# CC27x0 register map
File version: 1.0
CPU: CM4 r0p4, little endian, no MPU, no FPU, VTOR, 3 interrupt priority bits
Registers are 32-bit, read-write, reset 0x0 unless marked. A register's access mark holds for its fields unless they carry their own. Offsets are from the block's base; [hi:lo] are bit positions; {n}, {i} and the like mark numbered series.

## SYS0 — This is top module of SYS0
Base 0x40004000
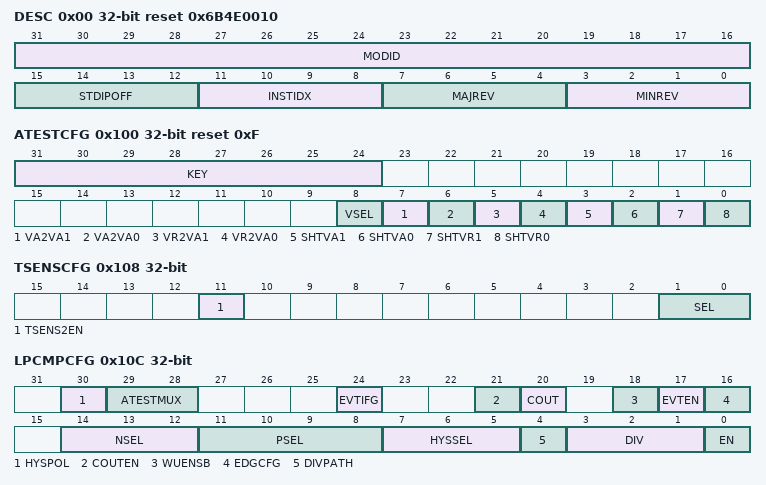
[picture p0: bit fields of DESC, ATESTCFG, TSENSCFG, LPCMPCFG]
0x00 DESC ro reset 0x6B4E0010 — Description Register This register provides IP module ID, revision information, instance index and standard MMR registers offset.
  [31:16] MODID — Module Identifier is used to uniquely identify this IP
  [15:12] STDIPOFF — Standard IP MMR block offset. Standard IP MMRs are the set from aggregated IRQ registers till DTB. 0: Standard IP MMRs do not exist 0x1-0xF: Standard IP MMRs begin at offset of (64*STDIPOFF from the base IP address)
  [11:8] INSTIDX — IP Instance ID number. If multiple instances of IP exist in the device, this field can identify the instance number (0-15).
  [7:4] MAJREV — Major revision of IP (0-15).
  [3:0] MINREV — Minor revision of IP (0-15).
0x0C MUNLOCK wo — Mutable section Unlock This register unlocks registers in mutable section
  [31:0] KEY — Write the unlock key 0xC5AF6927 to temporarily unlock registers in mutable section. The lock is set automatically if no write accesses, to the mutable section, are detected for consecutive 32 CLKULL (24MHz) clock cycles. Writing any value other than that, the unlock key will immediately lock the mutable register space for write access.
    0xC5AF6927=UNLOCK (Unlock registers in the mutable section); 0=LOCK (Lock registers in the mutable section)
0x100 ATESTCFG reset 0xF — ATEST Configuration This register is used to configure analog switches in ATEST module.
  [31:24] KEY wo — Key must be written with value 0x5A for successful write to ATESTCFG and to unlock register state. Write with any value other than 0x5A to KEY will be ignored and register content is not updated. It is recommended to write this register with incorrect KEY to lock back register state after necessary ATESTCFG updates are done. Read value of KEY is 0x0.
  [8] VSEL — Selects supply for ATEST switches.
    1=VDDS (Selects VDDS); 0=VDDBST (Selects VDDBOOST)
  [7] VA2VA1 — Enables isolation switch between VA_ATEST_A1 and VA_PAD_A1.
    1=CLOSE (Switch is closed); 0=OPEN (Switch is open)
  [6] VA2VA0 — Enables isolation switch between VA_ATEST_A0 and VA_PAD_A0.
    1=CLOSE (Switch is closed); 0=OPEN (Switch is open)
  [5] VR2VA1 — Enables isolation switch between VR_ATEST_A1 and VA_ATEST_A1.
    1=CLOSE (Switch is closed); 0=OPEN (Switch is open)
  [4] VR2VA0 — Enables isolation switch between VR_ATEST_A0 and VA_ATEST_A0.
    1=CLOSE (Switch is closed); 0=OPEN (Switch is open)
  [3] SHTVA1 — Shorts VA_ATEST_A1 to ground.
    1=CLOSE (Switch is closed); 0=OPEN (Switch is open)
  [2] SHTVA0 — Shorts VA_ATEST_A0 to ground.
    1=CLOSE (Switch is closed); 0=OPEN (Switch is open)
  [1] SHTVR1 — Shorts VR_ATEST_A1 to ground.
    1=CLOSE (Switch is closed); 0=OPEN (Switch is open)
  [0] SHTVR0 — Shorts VR_ATEST_A0 to ground.
    1=CLOSE (Switch is closed); 0=OPEN (Switch is open)
0x108 TSENSCFG — TSENSE Configuration This register is used to configure temperature sensor module.
  [11] TSENS2EN — This is the enable bit for the second temperature sensor in AUX.
    1=EN (Second temperature sensor is enabled.); 0=DIS (Second temperature sensor is disabled.)
  [1:0] SEL — Used to enable and configure temperature sensor module. Setting the value to 0x3 will disable the temperature sensor.
    2=GND (20uA current is injected on VR_ATEST_A0 and ground measured on VR_ATEST_A1); 1=VALUE (20uA current is injected on VR_ATEST_A0 and voltage measured on VR_ATEST_A1); 0=DISABLE (Temperature sensor is disabled)
0x10C LPCMPCFG — LPCMP configuration This register is used to configure and check the status of low-power comparator (LPCOMP) module.
  [30] HYSPOL — Hysteresis polarity
    1=INV (Inverted); 0=NOINV (Not inverted)
  [29:28] ATESTMUX — Used to configure ATEST mux in comparator module and provides chosen output on VA_ATEST_A0. Note: This bit field is write-protected using global lock indicator on production device.
    3=IBIASOUT (Selects bias current output); 2=COMP_VIN_NEG (Selects voltage divider output); 1=COMPOUT (Selects comparator output); 0=OFF (ATEST mux is off)
  [24] EVTIFG — Event flag The event flag is set when the comparator output transition is qualified based on the edge polarity configuration in EDGCFG.
    1=SET; 0=CLR (Clear)
  [21] COUTEN — Enables LPCOMP output on device pin.
    1=EN (Enabled); 0=DIS (Disabled)
  [20] COUT ro — LPCOMP output status. This bit captures the value LPCOMP raw output.
    1=HIGH (Output is high); 0=LOW (Output is low)
  [18] WUENSB — Enables lpcmpcfg output to wake device from standby.
    1=EN (Enable); 0=DIS (Disable)
  [17] EVTEN — Enables event generation. Comparator module will produce event on ULL event fabric when EVTIFG is set.
    1=EN (Enable); 0=DIS (Disable)
  [16] EDGCFG — Selects positive edge or negative edge detection on comparator output to set the event flag
    1=FALL (Fall edge detection); 0=RISE (Rise edge detection)
  [14:12] NSEL — Negative input selection. Setting values 0x5-0x7 will open all the switches.
    4=VDDD (Selects VDDD); 3=VDDS (Selects VDDS); 2=VA_PAD_A3 (Selects VA_PAD_A3); 1=VA_PAD_A2 (Selects VA_PAD_A2); 0=OPEN (All switches are open)
  [11:8] PSEL — Positive input selection. Setting values 0x9-0xF will open all the switches.
    8=VDDS (Selects VDDS); 7=VA_ATEST_A1 (Selects VA_ATEST_A1); 6=VA_ATEST_A0 (Selects VA_ATEST_A0); 5=VR_ATEST_A1 (Selects VR_ATEST_A1); 4=VR_ATEST_A0 (Selects VR_ATEST_A0); 3=VA_PAD_A3 (Selects VA_PAD_A3); 2=VA_PAD_A2 (Selects VA_PAD_A2); 1=VA_PAD_A1 (Selects VA_PAD_A1); 0=OPEN (All switches are open)
  [7:5] HYSSEL — Used to enable and select hysteresis level Hysteresis is disabled when HYSSEL = 0 and enabled for other values of HYSSEL from 1 to 7. Refer to device specific datasheet for individual hysteresis values.
    {v}=Hysteresis value {v} (v=1..7); 0=Hysteresis is disabled
  [4] DIVPATH — Used to select the path on which voltage divider is applied
    1=PSIDE (Divider is applied on P-side); 0=NSIDE (Divider is applied on N-side)
  [3:1] DIV — Used to configure reference divider. Setting values 0x5-0x7 will set the divide value to 1.
    4=Divide value is 1/4; 3=Divide value is 1/3; 2=Divide value is 1/2; 1=Divide value is 3/4; 0=Divide value is 1
  [0] EN — Used to enable comparator module.
    1=EN (Enable); 0=DIS (Disable)
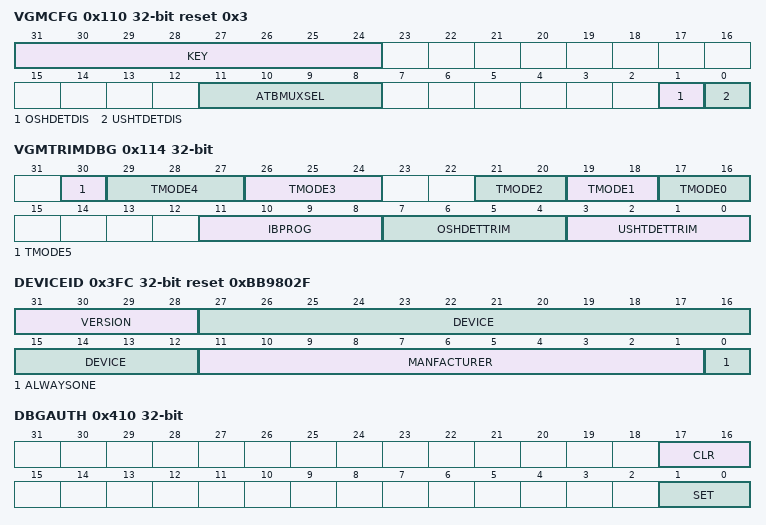
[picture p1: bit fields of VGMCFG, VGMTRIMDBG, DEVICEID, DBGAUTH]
0x110 VGMCFG reset 0x3 — This register is used to configure the VGM module.
  [31:24] KEY wo — Key must be written with value 0x5A for successful write to VGMCFG and to unlock register state. Write with any value other than 0x5A to KEY will be ignored and the register content is not updated. Read value of KEY is 0x0.
  [11:8] ATBMUXSEL — These bits are used to generate VGM ATB mux selection control.
  [1] OSHDETDIS — Disables overshoot detector in VGM.
    1=DIS (Disable); 0=EN (Enable)
  [0] USHTDETDIS — Disables undershoot detector in VGM.
    1=DIS (Disable); 0=EN (Enable)
0x114 VGMTRIMDBG — This register is used to trim and debug VGM module.
  [30] TMODE5 — Test mode bit for glitchy supply mux selection.
  [29:27] TMODE4 — Test mode bits for VREF mux selection for overshoot detector.
  [26:24] TMODE3 — Test mode bits for VREF mux selection for undershoot detector.
  [21:20] TMODE2 — Test mode for level shifter isolation.
  [19:18] TMODE1 — Test mode bits for low voltage SR latch reset.
  [17:16] TMODE0 — Test mode bits for 3V SR latch reset.
  [11:8] IBPROG — These bits are used to program VGM bias current generator.
  [7:4] OSHDETTRIM — These bits are used to trim VGM overshoot detector.
  [3:0] USHTDETTRIM — These bits are used to trim VGM undershoot detector.
0x3FC DEVICEID ro reset 0xBB9802F — Device ID This register provides Device ID information. Note: This 32-bit register value is provided as output to DEBUGSS.
  [31:28] VERSION — Monotonic increasing value indicating new hardware revision. A newer hardware revision shall never have a lower version than an older revision of hardware.
  [27:12] DEVICE — Value generated by RAMP for the SOC. This value uniquely identifies the die from any other TI device.
  [11:1] MANFACTURER — JEP 106 assigned manufacturer ID. This field identifies the device as a Texas Instruments device.
  [0] ALWAYSONE — Value 1 in this bit field means that a 32-bit scan register exists.
0x410 DBGAUTH wo — Debug Authentication. This register is used by ROM to store Debug Authnetication Status
  [17:16] CLR — Clears Authentication Status
  [1:0] SET — Sets Authentication Status
    3=SEC (Secure Debug Authorized); 2=NONSEC (Non-Secure Debug Authorized); 1=NONINV (Only Non-Invasive Debug Authorized); 0=UNAUTH (Debug Unauthorized)
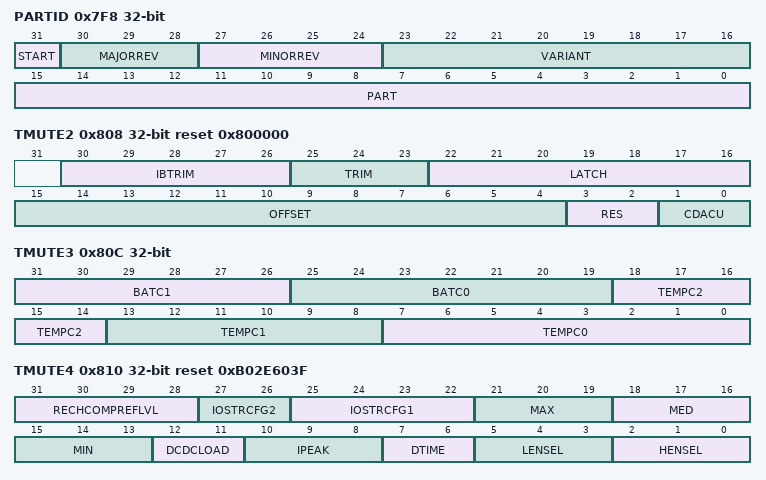
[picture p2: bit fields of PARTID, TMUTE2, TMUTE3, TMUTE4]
0x7F8 PARTID — Part ID This register is programmed by boot code with Part ID information. Note: This 32-bit register value is provided as output to DEBUGSS
  [31] START — Start bit
    1=SET; 0=CLR (Clear)
  [30:28] MAJORREV — Monotonic increasing value indicating a new revision of the SKU significant enough that users of the device may have to revise PCB or software design
  [27:24] MINORREV — Monotonic increasing value indicating a new revision of the SKU that preserves compatibility with lesser MINORREV values
  [23:16] VARIANT — Bit pattern uniquely identifying a variant of a part
  [15:0] PART — Bit pattern uniquely identifying a part
0x7FC LIFECYC — This register is programmed by boot code with device life cycle information
  [7:0] VAL — Device life cycle value.
    255=LCYCLE_ILLEGAL (Illegal); 6=LCYCLE_RETEST (Re-test); 5=LCYCLE_PRODDEV (Production device); 4=LCYCLE_ENGRDEV (Engineering device); 3=LCYCLE_TESTFT (Test Final Test); 2=LCYCLE_TESTPT (Test Production Test); 1=LCYCLE_1STBDAY (First birthday); 0=LCYCLE_POSSIBLE_1STBDAY (Possible first birthday)
0x800 TMUTE0 — Internal. Only to be used through TI provided API.
  [31:0] CDACL
0x804 TMUTE1 — Internal. Only to be used through TI provided API.
  [31:0] CDACM
0x808 TMUTE2 reset 0x800000 — TMUTE2 trim Register
  [30:26] IBTRIM — LPCOMP: Bias current trim, 250nA to be terminated across I2V, 1M ohm setting. Resulting target trim voltage 250mV.
  [25:23] TRIM — ADC REFBUF trim bits.
  [22:16] LATCH — SOC ADC: Latch trim bits. These bits are used in the analog IP.
  [15:4] OFFSET — SOCADC: Offset trim bits. These bits are used in DTC.
  [3:2] RES — SOCADC: Resistor trim bits. These bits are used in the analog IP.
  [1:0] CDACU — SOCADC: Upper 2 bits of CDAC trim. These bits are used in DTC.
0x80C TMUTE3 — Internal. Only to be used through TI provided API.
  [31:26] BATC1 — Internal. Only to be used through TI provided API.
  [25:19] BATC0 — Internal. Only to be used through TI provided API.
  [18:14] TEMPC2 — Internal. Only to be used through TI provided API.
  [13:8] TEMPC1 — Internal. Only to be used through TI provided API.
  [7:0] TEMPC0 — Internal. Only to be used through TI provided API.
0x810 TMUTE4 reset 0xB02E603F — TMUTE4 trim Register
  [31:28] RECHCOMPREFLVL — Internal. Only to be used through TI provided API.
  [27:26] IOSTRCFG2 — Internal. Only to be used through TI provided API.
  [25:22] IOSTRCFG1 — Internal. Only to be used through TI provided API.
  [21:19] MAX — Internal. Only to be used through TI provided API.
  [18:16] MED — Internal. Only to be used through TI provided API.
  [15:13] MIN — Internal. Only to be used through TI provided API.
  [12:11] DCDCLOAD — Internal. Only to be used through TI provided API.
  [10:8] IPEAK — Internal. Only to be used through TI provided API.
  [7:6] DTIME — Internal. Only to be used through TI provided API.
  [5:3] LENSEL — Internal. Only to be used through TI provided API.
  [2:0] HENSEL — Internal. Only to be used through TI provided API.
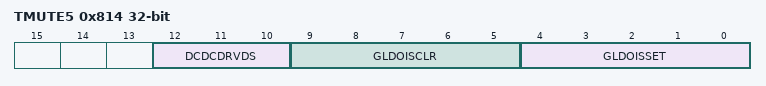
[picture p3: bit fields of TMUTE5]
0x814 TMUTE5 — Internal. Only to be used through TI provided API.
  [12:10] DCDCDRVDS — Internal. Only to be used through TI provided API.
  [9:5] GLDOISCLR wo — Internal. Only to be used through TI provided API.
  [4:0] GLDOISSET wo — Internal. Only to be used through TI provided API.
